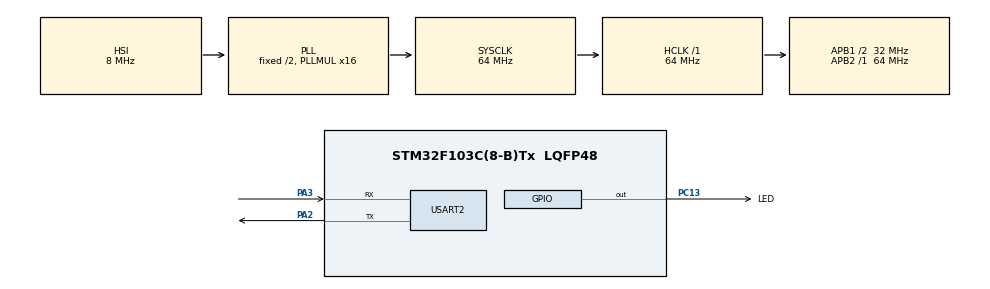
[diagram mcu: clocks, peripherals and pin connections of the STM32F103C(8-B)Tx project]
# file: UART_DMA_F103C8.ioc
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Dma.Request0=USART2_RX
Dma.USART2_RX.0.Direction=DMA_PERIPH_TO_MEMORY
Dma.USART2_RX.0.Instance=DMA1_Channel6
Dma.USART2_RX.0.MemDataAlignment=DMA_MDATAALIGN_BYTE
Dma.USART2_RX.0.MemInc=DMA_MINC_ENABLE
Dma.USART2_RX.0.Mode=DMA_NORMAL
Dma.USART2_RX.0.PeriphDataAlignment=DMA_PDATAALIGN_BYTE
Dma.USART2_RX.0.PeriphInc=DMA_PINC_DISABLE
Dma.USART2_RX.0.Priority=DMA_PRIORITY_LOW
Mcu.Family=STM32F1
Mcu.Name=STM32F103C(8-B)Tx
Mcu.Package=LQFP48
NVIC.DMA1_Channel6_IRQn=true\:0\:0\:false\:false\:true\:false\:true
NVIC.PriorityGroup=NVIC_PRIORITYGROUP_4
NVIC.USART2_IRQn=true\:0\:0\:false\:false\:true\:true\:true
PA13.Mode=Serial_Wire
PA13.Signal=SYS_JTMS-SWDIO
PA14.Mode=Serial_Wire
PA14.Signal=SYS_JTCK-SWCLK
PA2.Mode=Asynchronous
PA2.Signal=USART2_TX
PA3.Mode=Asynchronous
PA3.Signal=USART2_RX
PC13-TAMPER-RTC.GPIO_Label=LED
PC13-TAMPER-RTC.Signal=GPIO_Output
ProjectManager.HeapSize=0x200
ProjectManager.StackSize=0x400
ProjectManager.TargetToolchain=STM32CubeIDE
RCC.AHBFreq_Value=64000000
RCC.APB1CLKDivider=RCC_HCLK_DIV2
RCC.APB1Freq_Value=32000000
RCC.APB1TimFreq_Value=64000000
RCC.APB2Freq_Value=64000000
RCC.APB2TimFreq_Value=64000000
RCC.HCLKFreq_Value=64000000
RCC.PLLMUL=RCC_PLL_MUL16
RCC.SYSCLKFreq_VALUE=64000000
RCC.SYSCLKSource=RCC_SYSCLKSOURCE_PLLCLK
RCC.USBFreq_Value=64000000
USART2.VirtualMode=VM_ASYNC
board=custom

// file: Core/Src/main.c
/* USER CODE BEGIN Header */
/**
  ******************************************************************************
  * @file           : main.c
  * @brief          : Main program body
  ******************************************************************************
  * @attention
  *
  * <h2><center>&copy; Copyright (c) 2019 STMicroelectronics.
  * All rights reserved.</center></h2>
  *
  * This software component is licensed by ST under BSD 3-Clause license,
  * the "License"; You may not use this file except in compliance with the
  * License. You may obtain a copy of the License at:
  *                        opensource.org/licenses/BSD-3-Clause
  *
  ******************************************************************************
  *
  *  Created on: 09.12.2019
  *      Author: Mateusz Salamon
  *		 www.msalamon.pl
  *
  *      Website: https://msalamon.pl/odbieranie-uart-z-dma-na-f103-to-rowniez-jest-proste/
  *      GitHub:  https://github.com/lamik/UART_DMA_receiving_F103
  *      Contact: mateusz@msalamon.pl
*/
/* USER CODE END Header */

#include "main.h"
#include "dma.h"
#include "usart.h"
#include "gpio.h"

/* USER CODE BEGIN Includes */
#include "UART_DMA.h"
#include "string.h"
/* USER CODE END Includes */

/* USER CODE BEGIN PD */
UARTDMA_HandleTypeDef huartdma;
/* USER CODE END PD */

/* USER CODE BEGIN PV */
char ParseBuffer[8];
/* USER CODE END PV */

void SystemClock_Config(void);

int main(void)
{

  /* MCU Configuration--------------------------------------------------------*/

  /* Reset of all peripherals, Initializes the Flash interface and the Systick. */
  HAL_Init();

  /* Configure the system clock */
  SystemClock_Config();

  /* Initialize all configured peripherals */
  MX_GPIO_Init();
  MX_DMA_Init();
  MX_USART2_UART_Init();
  /* USER CODE BEGIN 2 */
  UARTDMA_Init(&huartdma, &huart2);
  /* USER CODE END 2 */

  /* Infinite loop */
  /* USER CODE BEGIN WHILE */
  while (1)
  {
	  if(UARTDMA_IsDataReady(&huartdma))
	  {
		  UARTDMA_GetLineFromBuffer(&huartdma, ParseBuffer);
		  if(strcmp(ParseBuffer, "ON") == 0)
		  {
			  HAL_GPIO_WritePin(LED_GPIO_Port, LED_Pin, GPIO_PIN_RESET);
		  }
		  else if(strcmp(ParseBuffer, "OFF")  == 0)
		  {
			  HAL_GPIO_WritePin(LED_GPIO_Port, LED_Pin, GPIO_PIN_SET);
		  }
	  }
    /* USER CODE END WHILE */

  }
}

void SystemClock_Config(void)
{
  RCC_OscInitTypeDef RCC_OscInitStruct = {0};
  RCC_ClkInitTypeDef RCC_ClkInitStruct = {0};

  /** Initializes the CPU, AHB and APB busses clocks
  */
  RCC_OscInitStruct.OscillatorType = RCC_OSCILLATORTYPE_HSI;
  RCC_OscInitStruct.HSIState = RCC_HSI_ON;
  RCC_OscInitStruct.HSICalibrationValue = RCC_HSICALIBRATION_DEFAULT;
  RCC_OscInitStruct.PLL.PLLState = RCC_PLL_ON;
  RCC_OscInitStruct.PLL.PLLSource = RCC_PLLSOURCE_HSI_DIV2;
  RCC_OscInitStruct.PLL.PLLMUL = RCC_PLL_MUL16;
  if (HAL_RCC_OscConfig(&RCC_OscInitStruct) != HAL_OK)
  {
    Error_Handler();
  }
  /** Initializes the CPU, AHB and APB busses clocks
  */
  RCC_ClkInitStruct.ClockType = RCC_CLOCKTYPE_HCLK|RCC_CLOCKTYPE_SYSCLK
                              |RCC_CLOCKTYPE_PCLK1|RCC_CLOCKTYPE_PCLK2;
  RCC_ClkInitStruct.SYSCLKSource = RCC_SYSCLKSOURCE_PLLCLK;
  RCC_ClkInitStruct.AHBCLKDivider = RCC_SYSCLK_DIV1;
  RCC_ClkInitStruct.APB1CLKDivider = RCC_HCLK_DIV2;
  RCC_ClkInitStruct.APB2CLKDivider = RCC_HCLK_DIV1;

  if (HAL_RCC_ClockConfig(&RCC_ClkInitStruct, FLASH_LATENCY_2) != HAL_OK)
  {
    Error_Handler();
  }
}

void Error_Handler(void)
{
}

/************************ (C) COPYRIGHT STMicroelectronics *****END OF FILE****/
